# iom480ae register map
Registers are 32-bit, access not given, no defined reset value unless marked. A register's access mark holds for its fields unless they carry their own. Addresses are absolute; registers are grouped by the start of their names; [hi:lo] are bit positions; {n}, {i} and the like mark numbered series.

## SPIM
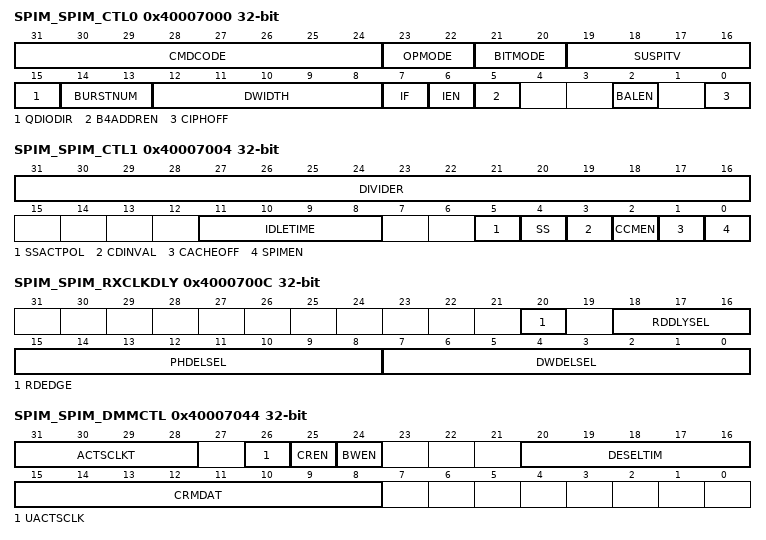
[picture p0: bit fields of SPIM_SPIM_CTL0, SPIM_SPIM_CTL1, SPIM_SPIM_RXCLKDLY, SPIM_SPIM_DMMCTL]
0x40007000 SPIM_SPIM_CTL0
  [31:24] CMDCODE, [23:22] OPMODE, [21:20] BITMODE, [19:16] SUSPITV, [15] QDIODIR, [14:13] BURSTNUM, [12:8] DWIDTH, [7] IF, [6] IEN, [5] B4ADDREN, [2] BALEN, [0] CIPHOFF
0x40007004 SPIM_SPIM_CTL1
  [31:16] DIVIDER, [11:8] IDLETIME, [5] SSACTPOL, [4] SS, [3] CDINVAL, [2] CCMEN, [1] CACHEOFF, [0] SPIMEN
0x4000700C SPIM_SPIM_RXCLKDLY
  [20] RDEDGE, [18:16] RDDLYSEL, [15:8] PHDELSEL, [7:0] DWDELSEL
{0x40007010+4i} SPIM_SPIM_RX{i} (i=0..3)
{0x40007020+4i} SPIM_SPIM_TX{i} (i=0..3)
0x40007030 SPIM_SPIM_SRAMADDR
0x40007034 SPIM_SPIM_DMACNT
  [23:0] DMACNT
0x40007038 SPIM_SPIM_FADDR
0x4000703C SPIM_SPIM_KEY1
0x40007040 SPIM_SPIM_KEY2
0x40007044 SPIM_SPIM_DMMCTL
  [31:28] ACTSCLKT, [26] UACTSCLK, [25] CREN, [24] BWEN, [20:16] DESELTIM, [15:8] CRMDAT
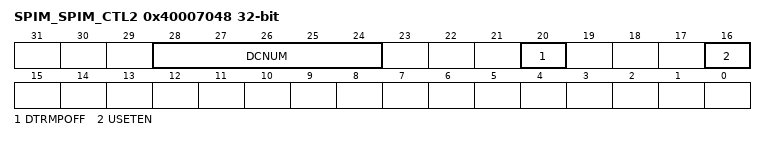
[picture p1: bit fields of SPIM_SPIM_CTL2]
0x40007048 SPIM_SPIM_CTL2
  [28:24] DCNUM, [20] DTRMPOFF, [16] USETEN

## I2C0
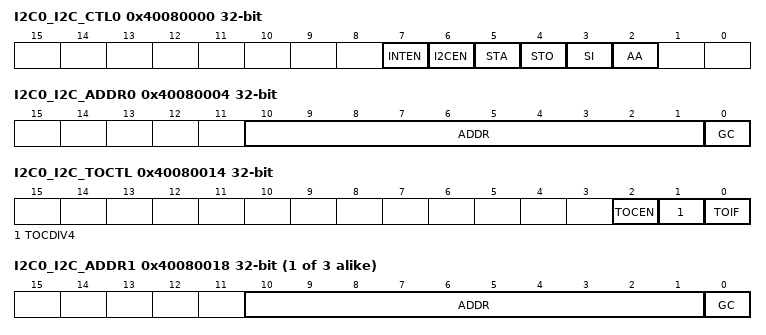
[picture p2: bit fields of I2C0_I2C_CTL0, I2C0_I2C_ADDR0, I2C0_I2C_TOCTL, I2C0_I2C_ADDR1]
0x40080000 I2C0_I2C_CTL0
  [7] INTEN, [6] I2CEN, [5] STA, [4] STO, [3] SI, [2] AA
0x40080004 I2C0_I2C_ADDR0
  [10:1] ADDR, [0] GC
0x40080008 I2C0_I2C_DAT
  [7:0] DAT
0x4008000C I2C0_I2C_STATUS0
  [7:0] STATUS
0x40080010 I2C0_I2C_CLKDIV
  [9:0] DIVIDER
0x40080014 I2C0_I2C_TOCTL
  [2] TOCEN, [1] TOCDIV4, [0] TOIF
{0x40080014+4i} I2C0_I2C_ADDR{i} (i=1..3)
  [10:1] ADDR, [0] GC
{0x40080024+4i} I2C0_I2C_ADDRMSK{i} (i=0..3)
  [10:1] ADDRMSK
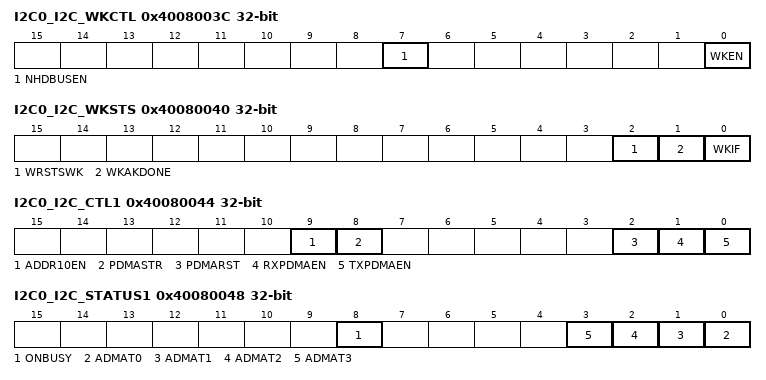
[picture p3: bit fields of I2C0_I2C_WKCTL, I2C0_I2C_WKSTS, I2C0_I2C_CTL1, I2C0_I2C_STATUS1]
0x4008003C I2C0_I2C_WKCTL
  [7] NHDBUSEN, [0] WKEN
0x40080040 I2C0_I2C_WKSTS
  [2] WRSTSWK, [1] WKAKDONE, [0] WKIF
0x40080044 I2C0_I2C_CTL1
  [9] ADDR10EN, [8] PDMASTR, [2] PDMARST, [1] RXPDMAEN, [0] TXPDMAEN
0x40080048 I2C0_I2C_STATUS1
  [8] ONBUSY, [n] ADMAT{n} (n=0..3)
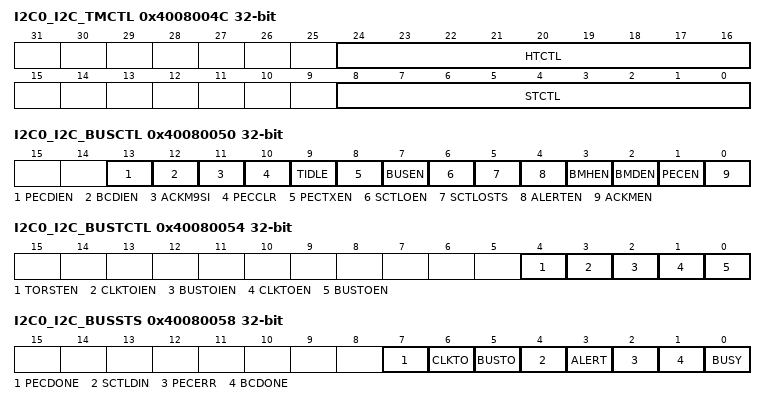
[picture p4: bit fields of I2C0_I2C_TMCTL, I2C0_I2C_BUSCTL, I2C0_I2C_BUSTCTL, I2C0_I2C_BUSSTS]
0x4008004C I2C0_I2C_TMCTL
  [24:16] HTCTL, [8:0] STCTL
0x40080050 I2C0_I2C_BUSCTL
  [13] PECDIEN, [12] BCDIEN, [11] ACKM9SI, [10] PECCLR, [9] TIDLE, [8] PECTXEN, [7] BUSEN, [6] SCTLOEN, [5] SCTLOSTS, [4] ALERTEN, [3] BMHEN, [2] BMDEN, [1] PECEN, [0] ACKMEN
0x40080054 I2C0_I2C_BUSTCTL
  [4] TORSTEN, [3] CLKTOIEN, [2] BUSTOIEN, [1] CLKTOEN, [0] BUSTOEN
0x40080058 I2C0_I2C_BUSSTS
  [7] PECDONE, [6] CLKTO, [5] BUSTO, [4] SCTLDIN, [3] ALERT, [2] PECERR, [1] BCDONE, [0] BUSY
0x4008005C I2C0_I2C_PKTSIZE
  [8:0] PLDSIZE
0x40080060 I2C0_I2C_PKTCRC
  [7:0] PECCRC
0x40080064 I2C0_I2C_BUSTOUT
  [7:0] BUSTO
0x40080068 I2C0_I2C_CLKTOUT
  [7:0] CLKTO

## I2C1
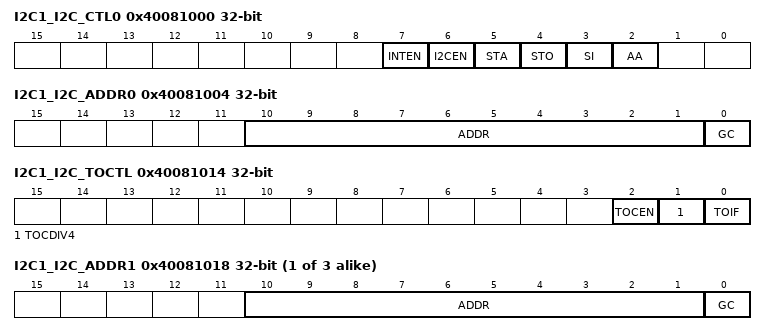
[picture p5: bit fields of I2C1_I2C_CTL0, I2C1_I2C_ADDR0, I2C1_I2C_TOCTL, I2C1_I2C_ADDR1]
0x40081000 I2C1_I2C_CTL0
  [7] INTEN, [6] I2CEN, [5] STA, [4] STO, [3] SI, [2] AA
0x40081004 I2C1_I2C_ADDR0
  [10:1] ADDR, [0] GC
0x40081008 I2C1_I2C_DAT
  [7:0] DAT
0x4008100C I2C1_I2C_STATUS0
  [7:0] STATUS
0x40081010 I2C1_I2C_CLKDIV
  [9:0] DIVIDER
0x40081014 I2C1_I2C_TOCTL
  [2] TOCEN, [1] TOCDIV4, [0] TOIF
{0x40081014+4i} I2C1_I2C_ADDR{i} (i=1..3)
  [10:1] ADDR, [0] GC
{0x40081024+4i} I2C1_I2C_ADDRMSK{i} (i=0..3)
  [10:1] ADDRMSK
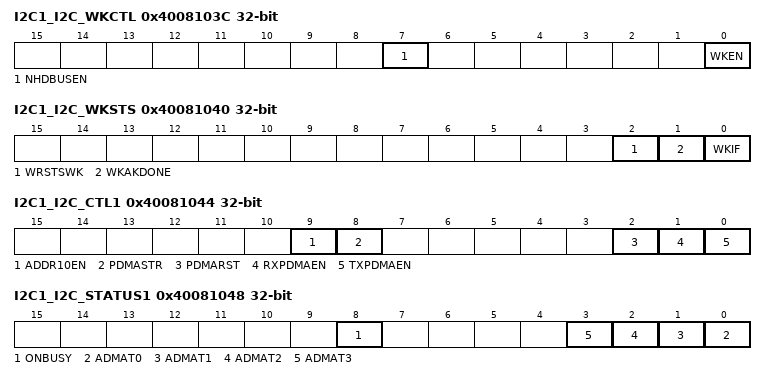
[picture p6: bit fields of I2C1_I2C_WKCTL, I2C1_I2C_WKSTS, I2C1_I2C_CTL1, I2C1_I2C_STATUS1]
0x4008103C I2C1_I2C_WKCTL
  [7] NHDBUSEN, [0] WKEN
0x40081040 I2C1_I2C_WKSTS
  [2] WRSTSWK, [1] WKAKDONE, [0] WKIF
0x40081044 I2C1_I2C_CTL1
  [9] ADDR10EN, [8] PDMASTR, [2] PDMARST, [1] RXPDMAEN, [0] TXPDMAEN
0x40081048 I2C1_I2C_STATUS1
  [8] ONBUSY, [n] ADMAT{n} (n=0..3)
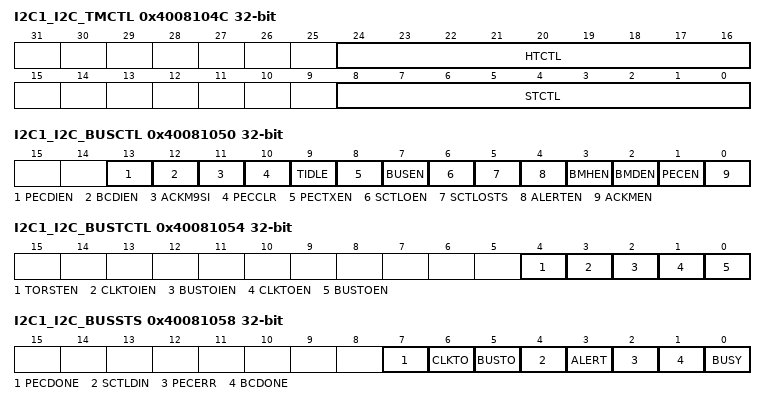
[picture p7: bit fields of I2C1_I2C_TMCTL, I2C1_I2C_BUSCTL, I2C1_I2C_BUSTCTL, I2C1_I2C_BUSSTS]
0x4008104C I2C1_I2C_TMCTL
  [24:16] HTCTL, [8:0] STCTL
0x40081050 I2C1_I2C_BUSCTL
  [13] PECDIEN, [12] BCDIEN, [11] ACKM9SI, [10] PECCLR, [9] TIDLE, [8] PECTXEN, [7] BUSEN, [6] SCTLOEN, [5] SCTLOSTS, [4] ALERTEN, [3] BMHEN, [2] BMDEN, [1] PECEN, [0] ACKMEN
0x40081054 I2C1_I2C_BUSTCTL
  [4] TORSTEN, [3] CLKTOIEN, [2] BUSTOIEN, [1] CLKTOEN, [0] BUSTOEN
0x40081058 I2C1_I2C_BUSSTS
  [7] PECDONE, [6] CLKTO, [5] BUSTO, [4] SCTLDIN, [3] ALERT, [2] PECERR, [1] BCDONE, [0] BUSY
0x4008105C I2C1_I2C_PKTSIZE
  [8:0] PLDSIZE
0x40081060 I2C1_I2C_PKTCRC
  [7:0] PECCRC
0x40081064 I2C1_I2C_BUSTOUT
  [7:0] BUSTO
0x40081068 I2C1_I2C_CLKTOUT
  [7:0] CLKTO

## I2C2
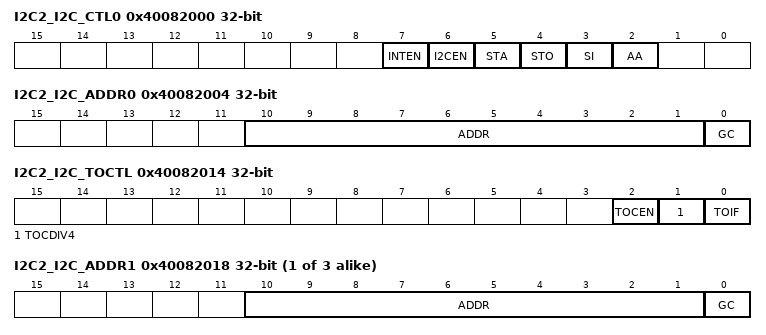
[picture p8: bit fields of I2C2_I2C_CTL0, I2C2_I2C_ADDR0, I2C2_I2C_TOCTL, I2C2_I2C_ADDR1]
0x40082000 I2C2_I2C_CTL0
  [7] INTEN, [6] I2CEN, [5] STA, [4] STO, [3] SI, [2] AA
0x40082004 I2C2_I2C_ADDR0
  [10:1] ADDR, [0] GC
0x40082008 I2C2_I2C_DAT
  [7:0] DAT
0x4008200C I2C2_I2C_STATUS0
  [7:0] STATUS
0x40082010 I2C2_I2C_CLKDIV
  [9:0] DIVIDER
0x40082014 I2C2_I2C_TOCTL
  [2] TOCEN, [1] TOCDIV4, [0] TOIF
{0x40082014+4i} I2C2_I2C_ADDR{i} (i=1..3)
  [10:1] ADDR, [0] GC
{0x40082024+4i} I2C2_I2C_ADDRMSK{i} (i=0..3)
  [10:1] ADDRMSK
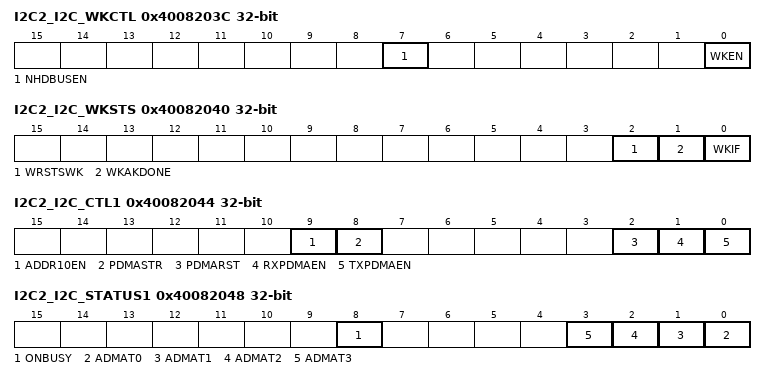
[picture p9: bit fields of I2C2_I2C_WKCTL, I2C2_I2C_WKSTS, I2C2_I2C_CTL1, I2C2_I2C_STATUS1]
0x4008203C I2C2_I2C_WKCTL
  [7] NHDBUSEN, [0] WKEN
0x40082040 I2C2_I2C_WKSTS
  [2] WRSTSWK, [1] WKAKDONE, [0] WKIF
0x40082044 I2C2_I2C_CTL1
  [9] ADDR10EN, [8] PDMASTR, [2] PDMARST, [1] RXPDMAEN, [0] TXPDMAEN
0x40082048 I2C2_I2C_STATUS1
  [8] ONBUSY, [n] ADMAT{n} (n=0..3)
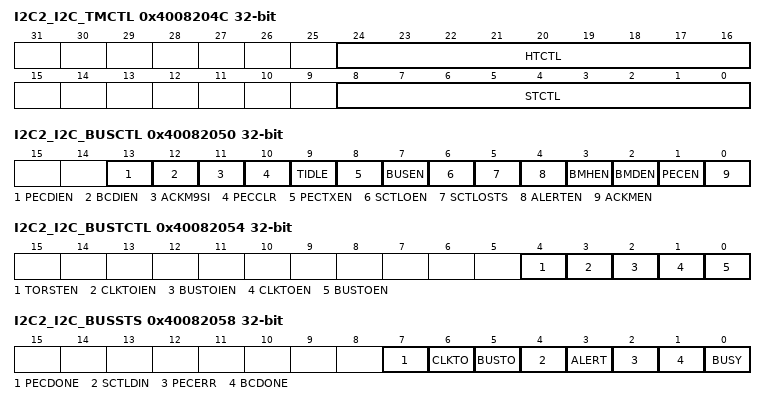
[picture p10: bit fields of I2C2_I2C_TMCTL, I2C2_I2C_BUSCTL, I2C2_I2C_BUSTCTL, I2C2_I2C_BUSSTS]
0x4008204C I2C2_I2C_TMCTL
  [24:16] HTCTL, [8:0] STCTL
0x40082050 I2C2_I2C_BUSCTL
  [13] PECDIEN, [12] BCDIEN, [11] ACKM9SI, [10] PECCLR, [9] TIDLE, [8] PECTXEN, [7] BUSEN, [6] SCTLOEN, [5] SCTLOSTS, [4] ALERTEN, [3] BMHEN, [2] BMDEN, [1] PECEN, [0] ACKMEN
0x40082054 I2C2_I2C_BUSTCTL
  [4] TORSTEN, [3] CLKTOIEN, [2] BUSTOIEN, [1] CLKTOEN, [0] BUSTOEN
0x40082058 I2C2_I2C_BUSSTS
  [7] PECDONE, [6] CLKTO, [5] BUSTO, [4] SCTLDIN, [3] ALERT, [2] PECERR, [1] BCDONE, [0] BUSY
0x4008205C I2C2_I2C_PKTSIZE
  [8:0] PLDSIZE
0x40082060 I2C2_I2C_PKTCRC
  [7:0] PECCRC
0x40082064 I2C2_I2C_BUSTOUT
  [7:0] BUSTO
0x40082068 I2C2_I2C_CLKTOUT
  [7:0] CLKTO
